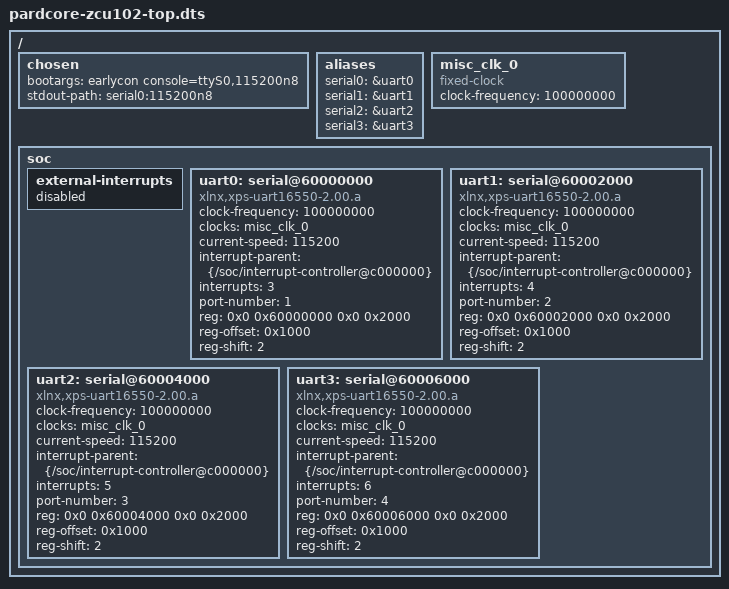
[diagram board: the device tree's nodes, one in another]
/include/ "freechips.rocketchip.system.TraceFPGAConfigzcu102.dts"

/ {
	chosen {
		bootargs = "earlycon console=ttyS0,115200n8";
		stdout-path = "serial0:115200n8";
	};
	aliases {
		serial0 = &uart0;
		serial1 = &uart1;
		serial2 = &uart2;
		serial3 = &uart3;
	};

	misc_clk_0: misc_clk_0 {
		#clock-cells = <0>;
		clock-frequency = <100000000>;
		compatible = "fixed-clock";
		status = "okay";
	};
	soc {
		/* TODO: Enable and route uart interrupts through this node */
		external-interrupts {
			status = "disabled";
		};

		/* TODO: Enable and make uartX children */
		/delete-node/ mmio-port-axi4@60000000;

		uart0: serial@60000000 {
			status = "okay";
			clock-frequency = <100000000>;
			clocks = <&misc_clk_0>;
			compatible = "xlnx,xps-uart16550-2.00.a", "ns16550a";
			current-speed = <115200>;
			device_type = "serial";
			interrupt-parent = <&{/soc/interrupt-controller@c000000}>;
			interrupts = <3>;
			port-number = <1>;
			reg = <0x0 0x60000000 0x0 0x2000>;
			reg-offset = <0x1000>;
			reg-shift = <2>;
		};
		uart1: serial@60002000 {
			status = "okay";
			clock-frequency = <100000000>;
			clocks = <&misc_clk_0>;
			compatible = "xlnx,xps-uart16550-2.00.a", "ns16550a";
			current-speed = <115200>;
			device_type = "serial";
			interrupt-parent = <&{/soc/interrupt-controller@c000000}>;
			interrupts = <4>;
			port-number = <2>;
			reg = <0x0 0x60002000 0x0 0x2000>;
			reg-offset = <0x1000>;
			reg-shift = <2>;
		};
		uart2: serial@60004000 {
			status = "okay";
			clock-frequency = <100000000>;
			clocks = <&misc_clk_0>;
			compatible = "xlnx,xps-uart16550-2.00.a", "ns16550a";
			current-speed = <115200>;
			device_type = "serial";
			interrupt-parent = <&{/soc/interrupt-controller@c000000}>;
			interrupts = <5>;
			port-number = <3>;
			reg = <0x0 0x60004000 0x0 0x2000>;
			reg-offset = <0x1000>;
			reg-shift = <2>;
		};
		uart3: serial@60006000 {
			status = "okay";
			clock-frequency = <100000000>;
			clocks = <&misc_clk_0>;
			compatible = "xlnx,xps-uart16550-2.00.a", "ns16550a";
			current-speed = <115200>;
			device_type = "serial";
			interrupt-parent = <&{/soc/interrupt-controller@c000000}>;
			interrupts = <6>;
			port-number = <4>;
			reg = <0x0 0x60006000 0x0 0x2000>;
			reg-offset = <0x1000>;
			reg-shift = <2>;
		};
	};
};
